# DCAN2 register map
Vendor: Texas Instruments
Registers are 32-bit, read-only, reset 0x0 unless marked. A register's access mark holds for its fields unless they carry their own. Offsets are as the file gives them; [hi:lo] are bit positions; {n}, {i} and the like mark numbered series; 'fields as' and 'values as' point back to an identical list.

## DCAN2 (part 2 of 2)
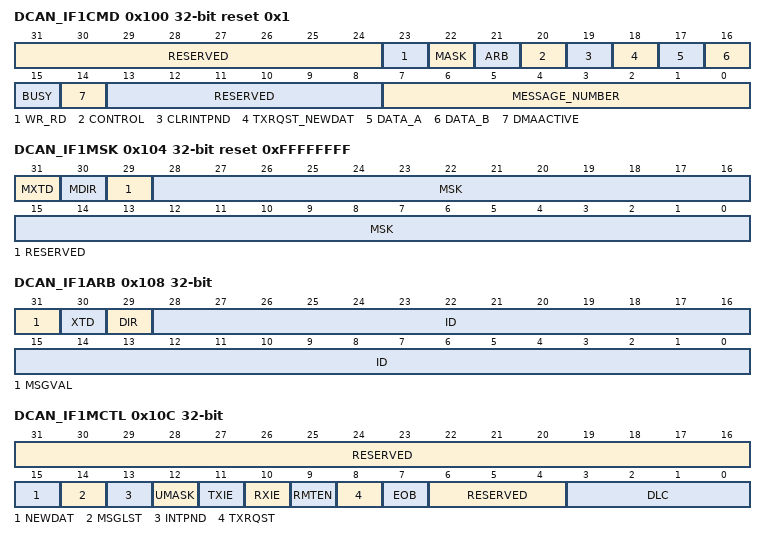
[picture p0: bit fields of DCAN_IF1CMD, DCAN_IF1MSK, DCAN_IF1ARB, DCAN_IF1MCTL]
0x100 DCAN_IF1CMD access per field reset 0x1 — IF1 Command Register The IF1 Command Register () configure and initiate the transfer between the IF1 register set and the message RAM. It is configurable which portions of the message object should be transferred. A transfer is started when the software writes the message number to bits [7:0] MESSAGE_NUMBER. With this write operation, the BUSY bit is automatically set to 1 to indicate that a transfer is in progress. After 4 to 14 OCP clock cycles, the transfer between the interface register and the message RAM will be completed and the BUSY bit is cleared. The maximum number of cycles is needed when the message transfer concurs with a CAN message transmission, acceptance filtering, or message storage. If the software writes to both / consecutively (request of a second transfer while first transfer is still in progress), the second transfer will start after the first one has been completed. While BUSY bit is one, IF1/IF2 register sets are write protected. For debug support, the auto clear functionality of the IF1/IF2 command registers (clear of DMAACTIVE flag by r/w) is disabled during Debug/Suspend mode. If an invalid Message Number is written to bits [7:0] MESSAGE_NUMBER, the message handler may access an implemented (valid) message object instead.
  [31:24] RESERVED ro — These bits are always read as 0. Writes have no effect.
  [23] WR_RD rw — Write/Read
    0=MESSAGE_NUMBER_IF1_0 (Direction = Read: Transfer direction is from the message object addressed by MESSAGE_NUMBER to the IF1 register set.); 1=IF1_MESSAGE_NUMBER._1 (Direction = Write: Transfer direction is from the IF1 register set to the message object addressed by MESSAGE_NUMBER.)
  [22] MASK rw — Access mask bits
    0=Mask_bits_will_not_be_changed; 1=MESSAGE_NUMBER_IF1_1 (Direction = Read: The mask bits (identifier mask + MDir + MXtd) will be transferred from the message object addressed by MESSAGE_NUMBER to the IF1 register set.); 1=IF1_MESSAGE_NUMBER._1 (Direction = Write: The mask bits (identifier mask + MDir + MXtd) will be transferred from the IF1 register set to the message object addressed by MESSAGE_NUMBER.)
  [21] ARB rw — Access arbitration bits
    0=Arbitration_bits_will_not_be_changed; 1=MESSAGE_NUMBER_IF1_1 (Direction = Read: The Arbitration bits (Identifier + Dir + Xtd + MsgVal) will be transferred from the message object addressed by MESSAGE_NUMBER to the corresponding IF1 register set.); 1=IF1_MESSAGE_NUMBER._1 (Direction = Write: The Arbitration bits (Identifier + Dir + Xtd + MsgVal) will be transferred from the IF1 register set to the message object addressed by MESSAGE_NUMBER.)
  [20] CONTROL rw — Access control bitsIf the TXRQST_NEWDAT bit in this register(Bit [18]) is set, the TXRQST/ NEWDAT bits in the will be ignored. .
    0=Control_bits_will_not_be_changed; 1=MESSAGE_NUMBER_IF1_1 (Direction = Read: The message control bits will be transferred from the message object addressed by MESSAGE_NUMBER to the IF1 register set.); 1=IF1_MESSAGE_NUMBER._1 (Direction = Write: The message control bits will be transferred from the IF1 registerset to the message object addressed by MESSAGE_NUMBER.)
  [19] CLRINTPND rw — Clear interrupt pending bit
    0=IntPnd_bit_will_not_be_changed; 1=Direction = Read: Clears IntPnd bit in the message object; 1=IF1_RAM_CONTROL_1 (Direction = Write: This bit is ignored. Copying of IntPnd flag from IF1 Registers to message RAM can only be controlled by the CONTROL flag (Bit [20]).)
  [18] TXRQST_NEWDAT rw — Access transmission request bitNote: If a CAN transmission is requested by setting TXRQST_NEWDAT in this register, the TxRqst/NewDat bits in the message object will be set to one independent of the values in. . Note: A read access to a message object can be combined with the reset of the control bits IntPnd and NewDat. The values of these bits transferred to the always reflect the status before resetting them. .
    0=CONTROL_0 (Direction = Read: NewDat bit will not be changed. Direction = Write: TxRqst/NewDat bit will be handled according to the CONTROL bit.); 1=Direction = Read: Clears NewDat bit in the message object. 1: Direction = Write: Sets TxRqst/NewDat in message object.
  [17] DATA_A rw — Access Data Bytes 0-3Note: The duration of the message transfer is independent of the number of bytes to be transferred. .
    0=Data_Bytes_0-3_will_not_be_changed; 1=MESSAGE_NUMBER_IF1_1 (Direction = Read: The data bytes 0-3 will be transferred from the message object addressed by the MESSAGE_NUMBER to the corresponding IF1 registerset.); 1=IF1_MESSAGE_NUMBER._1 (Direction = Write: The data bytes 0-3 will be transferred from the IF1 registerset to the message object addressed by the MESSAGE_NUMBER.)
  [16] DATA_B rw — Access Data Bytes 4-7Note: The duration of the message transfer is independent of the number of bytes to be transferred. .
    0=Data_Bytes_4-7_will_not_be_changed; 1=MESSAGE_NUMBER_IF1_1 (Direction = Read: The data bytes 4-7 will be transferred from the message object addressed by MESSAGE_NUMBER to the corresponding IF1 registerset.); 1=IF1_MESSAGE_NUMBER._1 (Direction = Write: The data bytes 4-7 will be transferred from the IF1 registerset to the message object addressed by MESSAGE_NUMBER.)
  [15] BUSY rw — Busy flagThis bit is set to one after the message number has been written to bits [7:0] MESSAGE_NUMBER. IF1 register set will be write protected. The bit is cleared after read/write action has been finished. .
    0=IF1_RAM_0 (No transfer between IF1 register set and message RAM is in progress.); 1=IF1_RAM_1 (Transfer between IF1 register set and message RAM is in progress.)
  [14] DMAACTIVE rw — Activation of DMA feature for subsequent internal IF1 updateThe DMA request remains active until the first read or write to one of the IF1 registers; an exception is a write to MESSAGE_NUMBER when DMAACTIVE is one. . Note: Due to the auto reset feature of the DMAACTIVE bit, this bit has to be set for each subsequent DMA cycle separately. .
    0=DMA_IF1_0 (DMA request line is independent of IF1 activities.); 1=DMA_IF1_RAM._1 (DMA is requested after completed transfer between IF1 register set and message RAM.)
  [13:8] RESERVED ro — These bits are always read as 0. Writes have no effect.
  [7:0] MESSAGE_NUMBER rw — Number of message object in message RAM which is used for data transfer0x01-0x80: Valid message numbers . 0x81-0xFF: Invalid message numbers .
    0=Invalid_message_number
0x104 DCAN_IF1MSK access per field reset 0xFFFFFFFF — IF1 Mask Register The bits of the IF1/IF2 mask registers mirror the mask bits of a message object. The function of the relevant message objects bits is described in Structure of Message Objects. While BUSY bit of / register is one, IF1/IF2 register set is write protected.
  [31] MXTD rw — Mask Extended IdentifierWhen 11-bit (“standard”) identifiers are used for a message object, the identifiers of received data frames are written into bits ID[28:18]. For acceptance filtering, only these bits together with mask bits Msk[28:18] are considered. .
    0=(IDE)_0 (The extended identifier bit (IDE) has no effect on the acceptance filtering.); 1=(IDE)_1 (The extended identifier bit (IDE) is used for acceptance filtering.)
  [30] MDIR rw — Mask Message Direction
    0=The message direction bit (Dir) has no effect on the acceptance filtering; 1=The message direction bit (Dir) is used for acceptance filtering
  [29] RESERVED ro — This bit is always read as 1. Writes have no effect.
  [28:0] MSK rw — Identifier Mask
    0=The corresponding bit in the identifier of the message object is not used for acceptance filtering (don't care); 1=The corresponding bit in the identifier of the message object is used for acceptance filtering
0x108 DCAN_IF1ARB rw — IF1 arbitration register The Arbitration bits ID[28:0], XTD, and DIR are used to define the identifier and type of outgoing messages and (together with the mask bits MSK[28:0], MXTD, and MDIR) for acceptance filtering of incoming messages. A received message is stored into the valid message object with matching identifier and Direction = receive (data frame) or Direction = transmit (remote frame). Extended frames can be stored only in message objects with XTD = 1, standard frames in message objects with XTD = 0. If a received message (data frame or remote frame) matches more than one valid message objects, it is stored into the one with the lowest message number. The bits of the IF1/IF2 arbitration registers mirror the arbitration bits of a message object. The function of the relevant message objects bits is described in Structure of Message Objects While BUSY bit of / register is one, IF1/IF2 register set is write protected.
  [31] MSGVAL — Message validThe software should reset the MsgVal bit of all unused Messages Objects during the initialization before it resets bit INIT in the. This bit must also be reset if the messages object is no longer required. .
    0=The message object is ignored by the message handler; 1=The message object is to be used by the message handler
  [30] XTD — Extended identifier
    0=The 11-bit (“standard”) Identifier is used for this message object; 1=The 29-bit (“extended”) Identifier is used for this message object
  [29] DIR — Message direction
    0=Direction = receive: On TxRqst, a remote frame with the identifier of this message object is transmitted. On reception of a data frame with matching identifier, this message is stored in this message object.; 1=Direction = transmit: On TxRqst, the respective message object is transmitted as a data frame. On reception of a remote frame with matching identifier, the TxRqst bit of this message object is set (if RmtEn = 1).
  [28:0] ID — Message identifierID[28:0]: 29-bit identifier (extended frame) . ID[28:18]: 11-bit identifier (standard frame) .
0x10C DCAN_IF1MCTL access per field — IF1 Message Control Register The bits of the IF1/IF2 message control registers mirror the message control bits of a message object. The function of the relevant message objects bits is described in Structure of Message Objects While BUSY bit of / register is one, IF1/IF2 register set is write protected.
  [31:16] RESERVED ro — These bits are always read as 0. Writes have no effect.
  [15] NEWDAT rw — New data
    0=No new data has been written into the data portion of this message object by the message handler since the last time when this flag was cleared by the software; 1=The message handler or the software has written new data into the data portion of this message object
  [14] MSGLST rw — Message lost (only valid for message objects with direction = receive)
    0=No message lost since the last time when this bit was reset by the software; 1=The message handler stored a new message into this object when NewDat was still set, so the previous message has been overwritten
  [13] INTPND rw — Interrupt pending
    0=This message object is not the source of an interrupt; 1=This message object is the source of an interrupt. The Interrupt Identifier in will point to this message object if there is no other interrupt source with higher priority.
  [12] UMASK rw — Use acceptance maskIf the UMASK bit is set to one, the message object's mask bits have to be programmed during initialization of the message object before MsgVal is set to one. .
    0=Mask_ignored; 1=Use mask (Msk[28:0], MXtd, and MDir) for acceptance filtering
  [11] TXIE rw — Transmit interrupt enable
    0=IntPnd will not be triggered after the successful transmission of a frame; 1=IntPnd will be triggered after the successful transmission of a frame
  [10] RXIE rw — Receive interrupt enable
    0=IntPnd will not be triggered after the successful reception of a frame; 1=IntPnd will be triggered after the successful reception of a frame
  [9] RMTEN rw — Remote enable
    0=At the reception of a remote frame, TxRqst is not changed; 1=At the reception of a remote frame, TxRqst is set
  [8] TXRQST rw — Transmit request
    0=This message object is not waiting for a transmission; 1=The transmission of this message object is requested and is not yet done
  [7] EOB rw — End of BlockNote: This bit is used to concatenate multiple message objects to build a FIFO Buffer. For single message objects (not belonging to a FIFO Buffer), this bit must always be set to 1. .
    0=FIFO_FIFO_0 (The message object is part of a FIFO Buffer block and is not the last message object of the FIFO Buffer block.); 1=FIFO_1 (The message object is a single message object or the last message object in a FIFO Buffer Block.)
  [6:4] RESERVED ro — These bits are always read as 0. Writes have no effect.
  [3:0] DLC rw — Data length code0-8: Data frame has 0-8 data bytes. . 9-15 Data frame has 8 data bytes. . Note: The data length code of a message object must be defined the same as in all the corresponding objects with the same identifier at other nodes. When the message handler stores a data frame, it will write the DLC to the value given by the received message. .
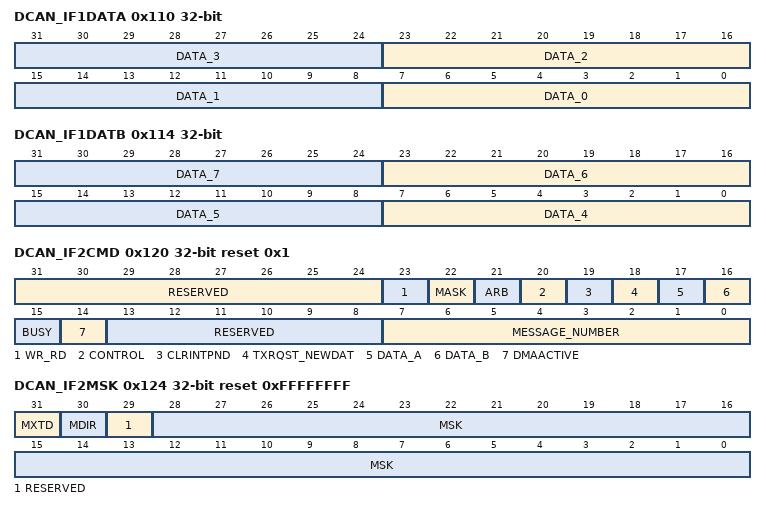
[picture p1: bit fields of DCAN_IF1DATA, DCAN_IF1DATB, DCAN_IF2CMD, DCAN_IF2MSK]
0x110 DCAN_IF1DATA rw — IF1 Data A Register The data bytes of CAN messages are stored in the IF1/IF2 registers in the following order: In a CAN data frame, Data 0 is the first, and Data 7 is the last byte to be transmitted or received. In CAN's serial bit stream, the MSB of each byte will be transmitted first. While BUSY bit of / register is one, IF1/IF2 register set is write protected.
  [8n+7:8n] DATA_{n} (n=0..3) — Data byte {n}
0x114 DCAN_IF1DATB rw — IF1 Data B Register The data bytes of CAN messages are stored in the IF1/IF2 registers in the following order: In a CAN data frame, Data 0 is the first, and Data 7 is the last byte to be transmitted or received. In CAN's serial bit stream, the MSB of each byte will be transmitted first. While BUSY bit of / register is one, IF1/IF2 register set is write protected.
  [8n-25:8n-32] DATA_{n} (n=4..7) — Data byte {n}
0x120 DCAN_IF2CMD access per field reset 0x1 — IF2 Command Register The IF2 Command Register () configure and initiate the transfer between the IF2 register set and the message RAM. It is configurable which portions of the message object should be transferred. A transfer is started when the software writes the message number to bits [7:0] MESSAGE_NUMBER. With this write operation, the BUSY bit is automatically set to 1 to indicate that a transfer is in progress. After 4 to 14 OCP clock cycles, the transfer between the interface register and the message RAM will be completed and the BUSY bit is cleared. The maximum number of cycles is needed when the message transfer concurs with a CAN message transmission, acceptance filtering, or message storage. If the software writes to both / consecutively (request of a second transfer while first transfer is still in progress), the second transfer will start after the first one has been completed. While BUSY bit is one, IF1/IF2 register sets are write protected. For debug support, the auto clear functionality of the IF1/IF2 command registers (clear of DMAACTIVE flag by r/w) is disabled during Debug/Suspend mode. If an invalid Message Number is written to bits [7:0] MESSAGE_NUMBER, the message handler may access an implemented (valid) message object instead.
  [31:24] RESERVED ro — These bits are always read as 0. Writes have no effect.
  [23] WR_RD rw — Write/Read
    0=MESSAGE_NUMBER_IF2_0 (Direction = Read: Transfer direction is from the message object addressed by MESSAGE_NUMBER to the IF2 register set.); 1=IF2_MESSAGE_NUMBER._1 (Direction = Write: Transfer direction is from the IF2 register set to the message object addressed by MESSAGE_NUMBER.)
  [22] MASK rw — Access mask bits
    0=Mask_bits_will_not_be_changed; 1=MESSAGE_NUMBER_IF2_1 (Direction = Read: The mask bits (identifier mask + MDir + MXtd) will be transferred from the message object addressed by MESSAGE_NUMBER to the IF2 register set.); 1=IF2_MESSAGE_NUMBER._1 (Direction = Write: The mask bits (identifier mask + MDir + MXtd) will be transferred from the IF2 register set to the message object addressed by MESSAGE_NUMBER.)
  [21] ARB rw — Access arbitration bits
    0=Arbitration_bits_will_not_be_changed; 1=MESSAGE_NUMBER_IF2_1 (Direction = Read: The Arbitration bits (Identifier + Dir + Xtd + MsgVal) will be transferred from the message object addressed by MESSAGE_NUMBER to the corresponding IF2 register set.); 1=IF2_MESSAGE_NUMBER._1 (Direction = Write: The Arbitration bits (Identifier + Dir + Xtd + MsgVal) will be transferred from the IF2 register set to the message object addressed by MESSAGE_NUMBER.)
  [20] CONTROL rw — Access control bitsIf the TXRQST_NEWDAT bit in this register(Bit [18]) is set, the TXRQST/ NEWDAT bits in the/ will be ignored. .
    0=Control_bits_will_not_be_changed; 1=MESSAGE_NUMBER_IF2_1 (Direction = Read: The message control bits will be transferred from the message object addressed by MESSAGE_NUMBER to the IF2 register set.); 1=IF2_MESSAGE_NUMBER._1 (Direction = Write: The message control bits will be transferred from the IF2 registerset to the message object addressed by MESSAGE_NUMBER.)
  [19] CLRINTPND rw — Clear interrupt pending bit
    0=IntPnd_bit_will_not_be_changed; 1=Direction = Read: Clears IntPnd bit in the message object; 1=IF2_RAM_CONTROL_1 (Direction = Write: This bit is ignored. Copying of IntPnd flag from IF2 Registers to message RAM can only be controlled by the CONTROL flag (Bit [20]).)
  [18] TXRQST_NEWDAT rw — Access transmission request bitNote: If a CAN transmission is requested by setting TXRQST_NEWDAT in this register, the TxRqst/NewDat bits in the message object will be set to one independent of the values in/. . Note: A read access to a message object can be combined with the reset of the control bits IntPnd and NewDat. The values of these bits transferred to the/ always reflect the status before resetting them. .
    values as DCAN_IF1CMD.TXRQST_NEWDAT
  [17] DATA_A rw — Access Data Bytes 0-3Note: The duration of the message transfer is independent of the number of bytes to be transferred. .
    0=Data_Bytes_0-3_will_not_be_changed; 1=MESSAGE_NUMBER_IF2_1 (Direction = Read: The data bytes 0-3 will be transferred from the message object addressed by the MESSAGE_NUMBER to the corresponding IF2 registerset.); 1=IF2_MESSAGE_NUMBER._1 (Direction = Write: The data bytes 0-3 will be transferred from the IF2 registerset to the message object addressed by the MESSAGE_NUMBER.)
  [16] DATA_B rw — Access Data Bytes 4-7Note: The duration of the message transfer is independent of the number of bytes to be transferred. .
    0=Data_Bytes_4-7_will_not_be_changed; 1=MESSAGE_NUMBER_IF2_1 (Direction = Read: The data bytes 4-7 will be transferred from the message object addressed by MESSAGE_NUMBER to the corresponding IF2 registerset.); 1=IF2_MESSAGE_NUMBER._1 (Direction = Write: The data bytes 4-7 will be transferred from the IF2 registerset to the message object addressed by MESSAGE_NUMBER.)
  [15] BUSY rw — Busy flagThis bit is set to one after the message number has been written to bits [7:0] MESSAGE_NUMBER. IF2 register set will be write protected. The bit is cleared after read/write action has been finished. .
    0=IF2_RAM_0 (No transfer between IF2 register set and message RAM is in progress.); 1=IF2_RAM_1 (Transfer between IF2 register set and message RAM is in progress.)
  [14] DMAACTIVE rw — Activation of DMA feature for subsequent internal IF2 updateThe DMA request remains active until the first read or write to one of the IF2 registers; an exception is a write to MESSAGE_NUMBER when DMAACTIVE is one. . Note: Due to the auto reset feature of the DMAACTIVE bit, this bit has to be set for each subsequent DMA cycle separately. .
    0=DMA_IF2_0 (DMA request line is independent of IF2 activities.); 1=DMA_IF2_RAM._1 (DMA is requested after completed transfer between IF2 register set and message RAM.)
  [13:8] RESERVED ro — These bits are always read as 0. Writes have no effect.
  [7:0] MESSAGE_NUMBER rw — Number of message object in message RAM which is used for data transfer0x01-0x80: Valid message numbers . 0x81-0xFF: Invalid message numbers .
    0=Invalid_message_number
0x124 DCAN_IF2MSK access per field reset 0xFFFFFFFF — IF2 Mask Register The bits of the IF1/IF2 mask registers mirror the mask bits of a message object. The function of the relevant message objects bits is described in Structure of Message Objects. While BUSY bit of / register is one, IF1/IF2 register set is write protected.
  fields as DCAN_IF1MSK
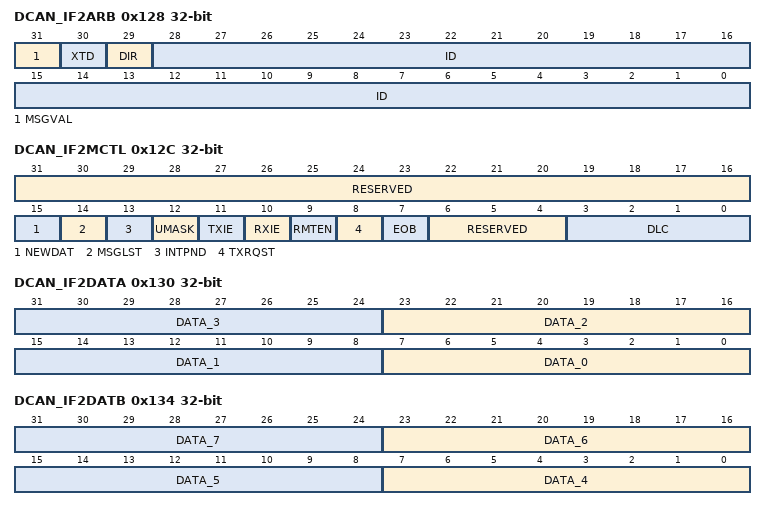
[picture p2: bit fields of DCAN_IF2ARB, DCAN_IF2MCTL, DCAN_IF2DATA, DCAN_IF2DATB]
0x128 DCAN_IF2ARB rw — IF2 arbitration register The Arbitration bits ID[28:0], XTD, and DIR are used to define the identifier and type of outgoing messages and (together with the mask bits MSK[28:0], MXTD, and MDIR) for acceptance filtering of incoming messages. A received message is stored into the valid message object with matching identifier and Direction = receive (data frame) or Direction = transmit (remote frame). Extended frames can be stored only in message objects with Xtd = 1, standard frames in message objects with Xtd = 0. If a received message (data frame or remote frame) matches more than one valid message objects, it is stored into the one with the lowest message number. The bits of the IF1/IF2 arbitration registers mirror the arbitration bits of a message object. The function of the relevant message objects bits is described in Structure of Message Objects While BUSY bit of / register is one, IF1/IF2 register set is write protected.
  fields as DCAN_IF1ARB
0x12C DCAN_IF2MCTL access per field — IF2 Message Control Register The bits of the IF1/IF2 message control registers mirror the message control bits of a message object. The function of the relevant message objects bits is described in Structure of Message Objects While BUSY bit of / register is one, IF1/IF2 register set is write protected.
  [31:16] RESERVED ro — These bits are always read as 0. Writes have no effect.
  [15] NEWDAT rw — New data
    values as DCAN_IF1MCTL.NEWDAT
  [14] MSGLST rw — Message lost (only valid for message objects with direction = receive)
    values as DCAN_IF1MCTL.MSGLST
  [13] INTPND rw — Interrupt pending
    values as DCAN_IF1MCTL.INTPND
  [12] UMASK rw — Use acceptance maskIf the UMask bit is set to one, the message object's mask bits have to be programmed during initialization of the message object before MsgVal is set to one. .
    values as DCAN_IF1MCTL.UMASK
  [11] TXIE rw — Transmit interrupt enable
    values as DCAN_IF1MCTL.TXIE
  [10] RXIE rw — Receive interrupt enable
    values as DCAN_IF1MCTL.RXIE
  [9] RMTEN rw — Remote enable
    values as DCAN_IF1MCTL.RMTEN
  [8] TXRQST rw — Transmit request
    values as DCAN_IF1MCTL.TXRQST
  [7] EOB rw — End of BlockNote: This bit is used to concatenate multiple message objects to build a FIFO Buffer. For single message objects (not belonging to a FIFO Buffer), this bit must always be set to one. .
    values as DCAN_IF1MCTL.EOB
  [6:4] RESERVED ro — These bits are always read as 0. Writes have no effect.
  [3:0] DLC rw — Data length code0-8: Data frame has 0-8 data bytes. . 9-15 Data frame has 8 data bytes. . Note: The data length code of a message object must be defined the same as in all the corresponding objects with the same identifier at other nodes. When the message handler stores a data frame, it will write the DLC to the value given by the received message. .
0x130 DCAN_IF2DATA rw — IF2 Data A Register The data bytes of CAN messages are stored in the IF1/IF2 registers in the following order: In a CAN data frame, Data 0 is the first, and Data 7 is the last byte to be transmitted or received. In CAN's serial bit stream, the MSB of each byte will be transmitted first. While BUSY bit of / register is one, IF1/IF2 register set is write protected.
  [8n+7:8n] DATA_{n} (n=0..3) — Data byte {n}
0x134 DCAN_IF2DATB rw — IF2 Data B Register The data bytes of CAN messages are stored in the IF1/IF2 registers in the following order: In a CAN data frame, Data 0 is the first, and Data 7 is the last byte to be transmitted or received. In CAN's serial bit stream, the MSB of each byte will be transmitted first. While BUSY bit of / register is one, IF1/IF2 register set is write protected.
  [8n-25:8n-32] DATA_{n} (n=4..7) — Data byte {n}
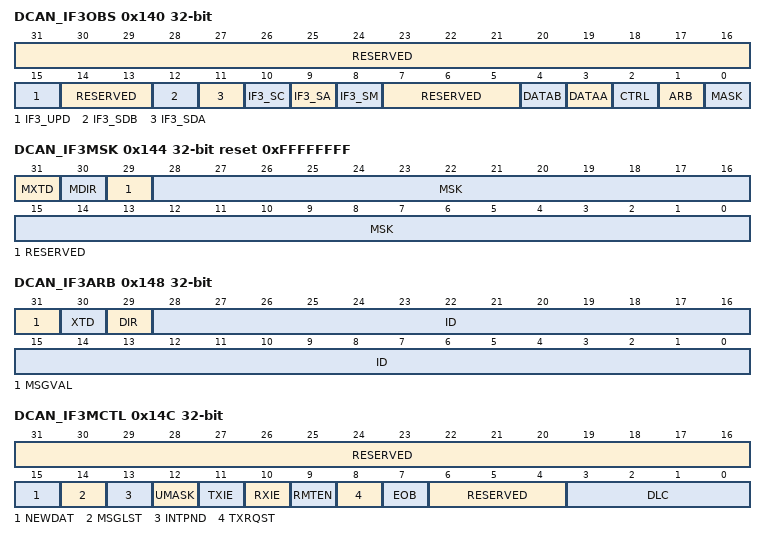
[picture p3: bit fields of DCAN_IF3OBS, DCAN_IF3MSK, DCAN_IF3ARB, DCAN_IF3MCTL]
0x140 DCAN_IF3OBS access per field — IF3 Observation Register The IF3 register set can automatically be updated with received message objects without the need to initiate the transfer from message RAM by software (Additional information can be found in NOTE: If IF3 Update Enable is used and no Observation flag is set, the corresponding message objects will be copied to IF3 without activating the DMA request line and without waiting for DMA read accesses. A write access to this register aborts a pending DMA cycle by resetting the DMA line and enables updating of IF3 interface register set with new data. To avoid data inconsistency, the DMA controller should be disabled before reconfiguring IF3 observation register. The status of the current read-cycle can be observed via status flags (Bits [12:8]).
  [31:16] RESERVED ro — These bits are always read as 0. Writes have no effect.
  [15] IF3_UPD ro — IF3 Update Data
    0=IF3_0 (No new data has been loaded since last IF3 read.); 1=IF3_1 (New data has been loaded since last IF3 read.)
  [14:13] RESERVED ro — These bits are always read as 0. Writes have no effect.
  [12] IF3_SDB ro — IF3 Status of Data B read access
    0=B_0 (All Data B bytes are already read out, or are not marked to be read.); 1=B_1 (Data B section has still data to be read out.)
  [11] IF3_SDA ro — IF3 Status of Data A read access
    0=A_0 (All Data A bytes are already read out, or are not marked to be read.); 1=A_1 (Data A section has still data to be read out.)
  [10] IF3_SC ro — IF3 Status of control bits read access
    0=All control section bytes are already read out, or are not marked to be read; 1=Control section has still data to be read out
  [9] IF3_SA ro — IF3 Status of Arbitration data read access
    0=All Arbitration data bytes are already read out, or are not marked to be read; 1=Arbitration section has still data to be read out
  [8] IF3_SM ro — IF3 Status of Mask data read access
    0=All mask data bytes are already read out, or are not marked to be read; 1=Mask section has still data to be read out
  [7:5] RESERVED ro — These bits are always read as 0. Writes have no effect.
  [4] DATAB rw — Data B read observation
    0=Data_B_section_has_not_to_be_read; 1=B_IF3_1 (Data B section has to be read to enable next IF3 update.)
  [3] DATAA rw — Data A read observation
    0=Data_A_section_has_not_to_be_read; 1=A_IF3_1 (Data A section has to be read to enable next IF3 update.)
  [2] CTRL rw — Ctrl read observation
    0=Ctrl_section_has_not_to_be_read; 1=IF3_1 (Ctrl section has to be read to enable next IF3 update.)
  [1] ARB rw — Arbitration data read observation
    0=Arbitration_data_has_not_to_be_read; 1=IF3_1 (Arbitration data has to be read to enable next IF3 update.)
  [0] MASK rw — Mask data read observation
    0=Mask_data_has_not_to_be_read; 1=IF3_1 (Mask data has to be read to enable next IF3 update.)
0x144 DCAN_IF3MSK access per field reset 0xFFFFFFFF — IF3 Mask Register
  [31] MXTD ro — Mask Extended IdentifierWhen 11-bit (“standard”) identifiers are used for a message object, the identifiers of received data frames are written into bits ID[28:18]. For acceptance filtering, only these bits together with mask bits Msk[28:18] are considered. .
    values as DCAN_IF1MSK.MXTD
  [30] MDIR ro — Mask Message Direction
    values as DCAN_IF1MSK.MDIR
  [29] RESERVED ro — These bits are always read as 1. Writes have no effect.
  [28:0] MSK rw — Identifier Mask
    values as DCAN_IF1MSK.MSK
0x148 DCAN_IF3ARB — IF3 Arbitration Register
  [31] MSGVAL — Message ValidThe software should reset the MsgVal bit of all unused Messages Objects during the initialization before it resets bit INIT in the. This bit must also be reset before the identifier ID[28:0], the control bits Xtd, Dir or DLC[3:0] are modified, or if the messages object is no longer required. .
    values as DCAN_IF1ARB.MSGVAL
  [30] XTD — Extended Identifier
    values as DCAN_IF1ARB.XTD
  [29] DIR — Message Direction
    values as DCAN_IF1ARB.DIR
  [28:0] ID — Message IdentifierID[28:0]: 29-bit Identifier (“extended frame”) . ID[28:18]: 11-bit Identifier (“standard frame”) .
0x14C DCAN_IF3MCTL — IF3 Message Control Register
  [31:16] RESERVED — These bits are always read as 0. Writes have no effect.
  [15] NEWDAT — New Data
    values as DCAN_IF1MCTL.NEWDAT
  [14] MSGLST — Message Lost (only valid for message objects with direction = receive)
    values as DCAN_IF1MCTL.MSGLST
  [13] INTPND — Interrupt Pending
    values as DCAN_IF1MCTL.INTPND
  [12] UMASK — Use Acceptance MaskIf the UMASK bit is set to one, the message object's mask bits have to be programmed during initialization of the message object before MsgVal is set to one. .
    values as DCAN_IF1MCTL.UMASK
  [11] TXIE — Transmit Interrupt enable
    values as DCAN_IF1MCTL.TXIE
  [10] RXIE — Receive Interrupt enable
    values as DCAN_IF1MCTL.RXIE
  [9] RMTEN — Remote enable
    values as DCAN_IF1MCTL.RMTEN
  [8] TXRQST — Transmit Request
    values as DCAN_IF1MCTL.TXRQST
  [7] EOB — End of BlockNote: This bit is used to concatenate multiple message objects to build a FIFO Buffer. For single message objects (not belonging to a FIFO Buffer), this bit must always be set to one. .
    values as DCAN_IF1MCTL.EOB
  [6:4] RESERVED — These bits are always read as 0. Writes have no effect.
  [3:0] DLC — Data Length Code0-8: Data frame has 0-8 data bits. . 9-15: Data frame has 8 data bytes. . Note: The data length code of a message object must be defined the same as in all the corresponding objects with the same identifier at other nodes. When the message handler stores a data frame, it will write the DLC to the value given by the received message. .
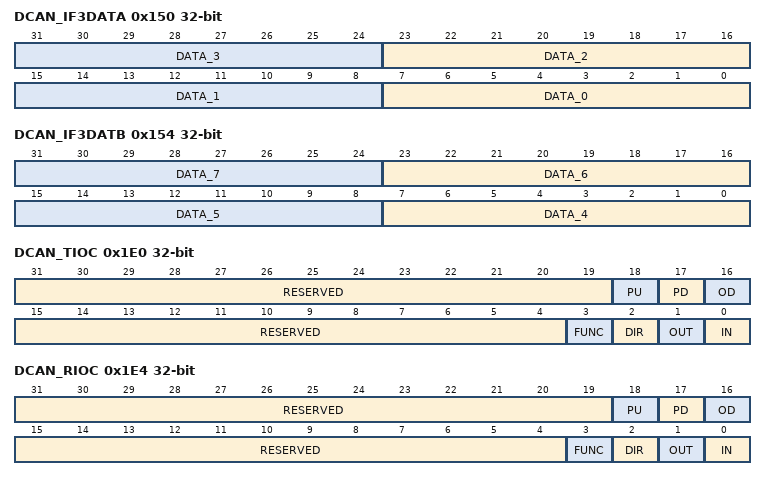
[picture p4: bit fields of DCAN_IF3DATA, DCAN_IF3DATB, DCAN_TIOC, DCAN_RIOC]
0x150 DCAN_IF3DATA — IF3 Data A The data bytes of CAN messages are stored in the IF3 registers in the following order: In a CAN data frame, Data 0 is the first, and Data 7 is the last byte to be transmitted or received. In CAN's serial bit stream, the MSB of each byte will be transmitted first.
  [8n+7:8n] DATA_{n} (n=0..3) — Data byte {n}
0x154 DCAN_IF3DATB — IF3 Data B The data bytes of CAN messages are stored in the IF3 registers in the following order: In a CAN data frame, Data 0 is the first, and Data 7 is the last byte to be transmitted or received. In CAN's serial bit stream, the MSB of each byte will be transmitted first.
  [8n-25:8n-32] DATA_{n} (n=4..7) — Data byte {n}
0x160 DCAN_IF3UPD12 rw — Update Enable Register The automatic update functionality of the IF3 register set can be configured for each message object. A message object is enabled for automatic IF3 update, if the dedicated IF3UPDEN flag is set. This means that an active NewDat flag of this message object (e.g due to reception of a CAN frame) will trigger an automatic copy of the whole message object to IF3 register set NOTE: IF3 Update enable should not be set for transmit objects.
  [31:0] IF3UPDEN — IF3 Update Enabled (for 1-32 message objects)
    0=IF3_0 (Automatic IF3 update is disabled for this message object.); 1=IF3_A_IF3_1 (Automatic IF3 update is enabled for this message object. A message object is scheduled to be copied to IF3 register set, if NewDat flag of the message object is active.)
0x164 DCAN_IF3UPD34 rw — Update Enable Register The automatic update functionality of the IF3 register set can be configured for each message object. A message object is enabled for automatic IF3 update, if the dedicated IF3UPDEN flag is set. This means that an active NewDat flag of this message object (e.g due to reception of a CAN frame) will trigger an automatic copy of the whole message object to IF3 register set NOTE: IF3 Update enable should not be set for transmit objects.
  [31:0] IF3UPDEN — IF3 Update Enabled (for 33-64 message objects)
    values as DCAN_IF3UPD12.IF3UPDEN
0x168 DCAN_IF3UPD56 rw — Update Enable Register The automatic update functionality of the IF3 register set can be configured for each message object. A message object is enabled for automatic IF3 update, if the dedicated IF3UPDEN flag is set. This means that an active NewDat flag of this message object (e.g due to reception of a CAN frame) will trigger an automatic copy of the whole message object to IF3 register set NOTE: IF3 Update enable should not be set for transmit objects.
  [31:0] IF3UPDEN — IF3 Update Enabled (for 65-96 message objects)
    values as DCAN_IF3UPD12.IF3UPDEN
0x16C DCAN_IF3UPD78 rw — Update Enable Register The automatic update functionality of the IF3 register set can be configured for each message object. A message object is enabled for automatic IF3 update, if the dedicated IF3UPDEN flag is set. This means that an active NewDat flag of this message object (e.g due to reception of a CAN frame) will trigger an automatic copy of the whole message object to IF3 register set NOTE: IF3 Update enable should not be set for transmit objects.
  [31:0] IF3UPDEN — IF3 Update Enabled (for 97-128 message objects)
    values as DCAN_IF3UPD12.IF3UPDEN
0x1E0 DCAN_TIOC access per field (reset mask 0xFFFFFFFE) — TX I/O Control Register The CAN_TX pin of the DCAN module can be used as general purpose IO pin if CAN function is not needed. The values of the IO control registers are only writable if INIT bit of the is set to 1.
  [31:19] RESERVED ro — These bits are always read as 0. Writes have no effect.
  [18] PU rw — CAN_TX pull up/pull down select. This bit is only active when CAN_TX is configured to be an input.
    0=CAN_TX_(PD_0 (CAN_TX pull down is selected, when pull logic is active (PD = 0).); 1=CAN_TX_1 (CAN_TX pull up is selected, when pull logic is active(PD = 0).)
  [17] PD rw — CAN_TX pull disable. This bit is only active when CAN_TX is configured to be an input.
    0=CAN_TX_pull_is_active; 1=CAN_TX_pull_is_disabled
  [16] OD rw — CAN_TX open drain enable. This bit is only active when CAN_TX is configured to be in GIO mode (FUNC=0).Forced to '0' if INIT bit of is reset. .
    0=CAN_TX_0 (The CAN_TX pin is configured in push/pull mode.); 1=CAN_TX_1 (The CAN_TX pin is configured in open drain mode.)
  [15:4] RESERVED ro — These bits are always read as 0. Writes have no effect.
  [3] FUNC rw — CAN_TX function. This bit changes the function of the CAN_TX pinForced to Tx output of the CAN core, if INIT bit of is reset. .
    0=CAN_TX_pin_is_in_GIO_mode; 1=CAN_TX_CAN_1 (CAN_TX pin is in functional mode (as an output to transmit CAN data).)
  [2] DIR rw — CAN_TX data direction. This bit controls the direction of the CAN_TX pin when it is configured to be in GIO mode only (FUNC=0)Forced to '1' if INIT bit of is reset. .
    0=The_CAN_TX_pin_is_an_input; 1=The_CAN_TX_pin_is_an_output
  [1] OUT rw — CAN_TX data out write. This bit is only active when CAN_TX pin is configured to be in GIO mode (FUNC = 0) and configured to be an output pin (DIR = 1). The value of this bit indicates the value to be output to the CAN_TX pin.Forced to 1 if INIT bit of is reset. .
    0=The_CAN_TX_pin_is_driven_to_logic_low; 1=The_CAN_TX_pin_is_driven_to_logic_high
  [0] IN rw — CAN_TX data inNote: When CAN_TX pin is connected to a CAN transceiver, an external pullup resistor has to be used to ensure that the CAN bus will not be disturbed (e.g. while reset of the DCAN module). .
    0=The_CAN_TX_pin_is_at_logic_low; 1=The_CAN_TX_pin_is_at_logic_high
0x1E4 DCAN_RIOC access per field (reset mask 0xFFFFFFFE) — RX I/O Control Register The CAN_RX pin of the DCAN_module can be used as general purpose IO pin if CAN function is not needed. The values of the IO control registers are only writable if INIT bit of the is set to 1.
  [31:19] RESERVED ro — These bits are always read as 0. Writes have no effect.
  [18] PU rw — CAN_RX pull up/pull down select. This bit is only active when CAN_RX is configured to be an input.
    0=CAN_RX_(PD_0 (CAN_RX pull down is selected, when pull logic is active (PD = 0).); 1=CAN_RX_1 (CAN_RX pull up is selected, when pull logic is active(PD = 0).)
  [17] PD rw — CAN_RX pull disable. This bit is only active when CAN_TX is configured to be an input.
    0=CAN_RX_pull_is_active; 1=CAN_RX_pull_is_disabled
  [16] OD rw — CAN_RX open drain enable. This bit is only active when CAN_RX is configured to be in GIO mode (FUNC=0).Forced to '0' if INIT bit of is reset. .
    0=CAN_RX_0 (The CAN_RX pin is configured in push/pull mode.); 1=CAN_RX_1 (The CAN_RX pin is configured in open drain mode.)
  [15:4] RESERVED ro — These bits are always read as 0. Writes have no effect.
  [3] FUNC rw — CAN_RX function. This bit changes the function of the CAN_RX pinForced to '1' if INIT bit of is reset. .
    0=CAN_RX_pin_is_in_GIO_mode; 1=CAN_RX_CAN_1 (CAN_RX pin is in functional mode (as an input to receive CAN data).)
  [2] DIR rw — CAN_RX data direction. This bit controls the direction of the CAN_RX pin when it is configured to be in GIO mode only (FUNC=0)Forced to '0' if INIT bit is reset. .
    0=The_CAN_RX_pin_is_an_input; 1=The_CAN_RX_pin_is_an_output
  [1] OUT rw — CAN_RX data out write. This bit is only active when CAN_RX pin is configured to be in GIO mode (FUNC = 0) and configured to be an output pin (DIR = 1). The value of this bit indicates the value to be output to the CAN_RX pin. .
    0=The_CAN_RX_pin_is_driven_to_logic_low; 1=The_CAN_RX_pin_is_driven_to_logic_high
  [0] IN rw — CAN_RX data in .
    0=The_CAN_RX_pin_is_at_logic_low; 1=The_CAN_RX_pin_is_at_logic_high
